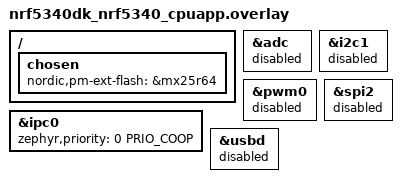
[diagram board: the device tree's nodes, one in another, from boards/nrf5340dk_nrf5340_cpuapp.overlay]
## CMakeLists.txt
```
#
# Copyright (c) 2023 Nordic Semiconductor ASA
#
# SPDX-License-Identifier: LicenseRef-Nordic-5-Clause
#

cmake_minimum_required(VERSION 3.20.0)

find_package(Zephyr HINTS $ENV{ZEPHYR_BASE})

project(matter-bridge)

# Enable GNU STD support.
include(${ZEPHYR_CONNECTEDHOMEIP_MODULE_DIR}/config/nrfconnect/app/enable-gnu-std.cmake)

# NORDIC SDK APP START

# Include all source files that are located in the Matter common directory.
include(${ZEPHYR_NRF_MODULE_DIR}/samples/matter/common/cmake/source_common.cmake)

# Include Data Model utils
include(${ZEPHYR_NRF_MODULE_DIR}/samples/matter/common/cmake/data_model.cmake)

include(${ZEPHYR_NRF_MODULE_DIR}/samples/matter/common/cmake/zap_helpers.cmake)
ncs_get_zap_parent_dir(ZAP_PARENT_DIR)

target_include_directories(app PRIVATE
  src
  src/bridged_device_types
  ${ZAP_PARENT_DIR}
  src/core/util
  src/core
)

target_sources(app PRIVATE
  src/app_task.cpp
  src/main.cpp
  src/bridge_shell.cpp
  src/zcl_callbacks.cpp
  src/core/bridge_manager.cpp
  src/core/matter_bridged_device.cpp
  src/core/bridge_storage_manager.cpp
  src/core/bridged_device_data_provider.cpp
  ${ZEPHYR_NRF_MODULE_DIR}/samples/matter/common/src/binding/binding_handler.cpp
)

if(CONFIG_BRIDGED_DEVICE_BT)
  target_sources(app PRIVATE
    src/ble/ble_connectivity_manager.cpp
    src/ble/ble_bridged_device_factory.cpp
  )
  target_include_directories(app PRIVATE
    src/ble
    src/ble/data_providers
  )

if(CONFIG_BRIDGE_ONOFF_LIGHT_BRIDGED_DEVICE AND (CONFIG_BRIDGE_GENERIC_SWITCH_BRIDGED_DEVICE OR CONFIG_BRIDGE_ONOFF_LIGHT_SWITCH_BRIDGED_DEVICE))
  target_sources(app PRIVATE
    src/bridged_device_types/onoff_light.cpp
    src/ble/data_providers/ble_lbs_data_provider.cpp
  )

if(CONFIG_BRIDGE_GENERIC_SWITCH_BRIDGED_DEVICE)
  target_sources(app PRIVATE src/bridged_device_types/generic_switch.cpp)
endif()

if(CONFIG_BRIDGE_ONOFF_LIGHT_SWITCH_BRIDGED_DEVICE)
  target_sources(app PRIVATE
    src/bridged_device_types/onoff_light_switch.cpp
  )
endif()

endif() # CONFIG_BRIDGE_ONOFF_LIGHT_BRIDGED_DEVICE AND (CONFIG_BRIDGE_GENERIC_SWITCH_BRIDGED_DEVICE OR CONFIG_BRIDGE_ONOFF_LIGHT_SWITCH_BRIDGED_DEVICE)

if(CONFIG_BRIDGE_HUMIDITY_SENSOR_BRIDGED_DEVICE)
  target_sources(app PRIVATE
    src/bridged_device_types/humidity_sensor.cpp
  )
endif() # CONFIG_BRIDGE_HUMIDITY_SENSOR_BRIDGED_DEVICE

if(CONFIG_BRIDGE_TEMPERATURE_SENSOR_BRIDGED_DEVICE)
  target_sources(app PRIVATE
    src/bridged_device_types/temperature_sensor.cpp
  )
endif() # CONFIG_BRIDGE_TEMPERATURE_SENSOR_BRIDGED_DEVICE

# Assume it makes no sense to support BLE environmental sensor without all Matter counterparts
if(CONFIG_BRIDGE_TEMPERATURE_SENSOR_BRIDGED_DEVICE AND CONFIG_BRIDGE_HUMIDITY_SENSOR_BRIDGED_DEVICE)
  target_sources(app PRIVATE
    src/ble/data_providers/ble_environmental_data_provider.cpp
)
endif() # CONFIG_BRIDGE_TEMPERATURE_SENSOR_BRIDGED_DEVICE AND CONFIG_BRIDGE_HUMIDITY_SENSOR_BRIDGED_DEVICE

else()
  target_sources(app PRIVATE
    src/simulated_providers/simulated_bridged_device_factory.cpp
  )
  target_include_directories(app PRIVATE src/simulated_providers)

if(CONFIG_BRIDGE_ONOFF_LIGHT_BRIDGED_DEVICE AND (CONFIG_BRIDGE_GENERIC_SWITCH_BRIDGED_DEVICE OR CONFIG_BRIDGE_ONOFF_LIGHT_SWITCH_BRIDGED_DEVICE))
  target_sources(app PRIVATE
    src/bridged_device_types/onoff_light.cpp
    src/simulated_providers/simulated_onoff_light_data_provider.cpp
  )

if(CONFIG_BRIDGE_GENERIC_SWITCH_BRIDGED_DEVICE)
  target_sources(app PRIVATE
    src/bridged_device_types/generic_switch.cpp
    src/simulated_providers/simulated_generic_switch_data_provider.cpp
  )
endif()

if(CONFIG_BRIDGE_ONOFF_LIGHT_SWITCH_BRIDGED_DEVICE)
  target_sources(app PRIVATE
    src/bridged_device_types/onoff_light_switch.cpp
    src/simulated_providers/simulated_onoff_light_switch_data_provider.cpp
  )
endif()

endif() # CONFIG_BRIDGE_ONOFF_LIGHT_BRIDGED_DEVICE AND (CONFIG_BRIDGE_GENERIC_SWITCH_BRIDGED_DEVICE OR CONFIG_BRIDGE_ONOFF_LIGHT_SWITCH_BRIDGED_DEVICE))

if(CONFIG_BRIDGE_TEMPERATURE_SENSOR_BRIDGED_DEVICE)
  target_sources(app PRIVATE
    src/bridged_device_types/temperature_sensor.cpp
    src/simulated_providers/simulated_temperature_sensor_data_provider.cpp
  )
endif() # CONFIG_BRIDGE_TEMPERATURE_SENSOR_BRIDGED_DEVICE

if(CONFIG_BRIDGE_HUMIDITY_SENSOR_BRIDGED_DEVICE)
  target_sources(app PRIVATE
    src/bridged_device_types/humidity_sensor.cpp
    src/simulated_providers/simulated_humidity_sensor_data_provider.cpp
  )
endif() # CONFIG_BRIDGE_HUMIDITY_SENSOR_BRIDGED_DEVICE

endif() # CONFIG_BRIDGED_DEVICE_BT

ncs_configure_data_model()
# NORDIC SDK APP END
```

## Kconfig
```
#
# Copyright (c) 2023 Nordic Semiconductor
#
# SPDX-License-Identifier: LicenseRef-Nordic-5-Clause
#
mainmenu "Matter nRF Connect Bridge Example Application"

config BRIDGE_ONOFF_LIGHT_BRIDGED_DEVICE
	bool "Support for OnOff Light bridged device"
	default y

config BRIDGE_TEMPERATURE_SENSOR_BRIDGED_DEVICE
	bool "Support for Temperature Sensor bridged device"
	default y

config BRIDGE_HUMIDITY_SENSOR_BRIDGED_DEVICE
	bool "Support for Humidity Sensor bridged device"
	default y

choice BRIDGE_SWITCH_BRIDGED_DEVICE
	prompt "Bridged device switch implementation"
	default BRIDGE_GENERIC_SWITCH_BRIDGED_DEVICE

config BRIDGE_GENERIC_SWITCH_BRIDGED_DEVICE
	bool "Support for Generic Switch bridged device"

config BRIDGE_ONOFF_LIGHT_SWITCH_BRIDGED_DEVICE
	bool "Support for OnOff Light Switch bridged device"

endchoice

choice BRIDGED_DEVICE_IMPLEMENTATION
	prompt "Bridged Device implementation"
	default BRIDGED_DEVICE_SIMULATED

config BRIDGED_DEVICE_SIMULATED
	bool "Simulated Bridged Device"
	help
	  Enables using simulated bridged devices that do not perform
	  real operations, but emulate exemplary data to imitate the real
	  device behavior.

config BRIDGED_DEVICE_BT
	bool "Bluetooth LE Bridged Device"
	help
	  Enables using real bridged devices that communicate with the Matter bridge device
	  over Bluetooth LE.

endchoice

if BRIDGED_DEVICE_SIMULATED

choice BRIDGED_DEVICE_SIMULATED_ONOFF_IMPLEMENTATION
	prompt "Simulated bridged onoff device implementation"
	default BRIDGED_DEVICE_SIMULATED_ONOFF_SHELL

config BRIDGED_DEVICE_SIMULATED_ONOFF_AUTOMATIC
	bool "Automatically simulated bridged onoff device"
	help
	  Enables using simulated bridged onoff device that
	  automatically changes its state periodically.

config BRIDGED_DEVICE_SIMULATED_ONOFF_SHELL
	bool "Shell controlled simulated bridged onoff device"
	help
	  Enables using simulated bridged onoff device that is
	  controlled by shell commands.

endchoice

endif

if BRIDGED_DEVICE_BT

config BT_CENTRAL
	default y

config BT_SCAN
	default y

# Configure how many Bluetooth LE devices the Matter bridge can support (the final number is given value - 1, as 1 connection is used for the Matter Bluetooth LE service).
config BT_MAX_CONN
	default 10

config BT_SCAN_FILTER_ENABLE
	default y

# Configure how many Bluetooth LE service UUIDs the Matter bridge can scan.
config BT_SCAN_UUID_CNT
	default 2

config BT_SCAN_ADDRESS_CNT
	default 1

config BT_GATT_CLIENT
	default y

config BT_GATT_DM
	default y

config BT_EXT_ADV
	default y

config BT_SMP
	default y

if BT_SMP

config BT_SETTINGS
	default y

# Configure how many Bluetooth LE devices will be paired with Matter bridge. Assuming it will be only bridged devices, it should be set to BT_MAX_CONN - 1.
config BT_MAX_PAIRED
	default 9

# Use two Bluetooth LE identities. The first one is used by the peripheral for Matter service advertising purposes, and the other is used by the Matter bridge central.
config BT_ID_MAX
	default 2

config BT_EXT_ADV_LEGACY_SUPPORT
	default y

endif

config BRIDGE_BLE_DEVICE_POLLING_INTERVAL
	int "BLE humidity measurement readout polling interval in ms"
	default 3000

endif

if BRIDGE_TEMPERATURE_SENSOR_BRIDGED_DEVICE

config BRIDGE_TEMPERATURE_SENSOR_MIN_MEASURED_VALUE
	int "Default minimum measured value allowed by the bridged temperature sensor device"
	default -20

config BRIDGE_TEMPERATURE_SENSOR_MAX_MEASURED_VALUE
	int "Default maximum measured value allowed by the bridged temperature sensor device"
	default 60

endif

if BRIDGE_HUMIDITY_SENSOR_BRIDGED_DEVICE

config BRIDGE_HUMIDITY_SENSOR_MIN_MEASURED_VALUE
	int "Default minimum measured value allowed by the bridged humidity sensor device"
	default 0

config BRIDGE_HUMIDITY_SENSOR_MAX_MEASURED_VALUE
	int "Default maximum measured value allowed by the bridged humidity sensor device"
	default 100

endif

# Enable Read Client functionality for all build configurations.
config CHIP_ENABLE_READ_CLIENT
	default y

config NCS_SAMPLE_MATTER_PERSISTENT_STORAGE
	default y

config BRIDGE_SMART_PLUG_SUPPORT
	bool "Additional endpoint implementing Matter smart plug functionality"

# Sample configuration used for Thread networking
if OPENTHREAD

choice OPENTHREAD_NORDIC_LIBRARY_CONFIGURATION
	default OPENTHREAD_NORDIC_LIBRARY_FTD
endchoice

choice OPENTHREAD_DEVICE_TYPE
	default OPENTHREAD_FTD
endchoice

endif # OPENTHREAD

config CHIP_WIFI
	default y if SHIELD_NRF7002EB2

# Dummy Kconfig just to select experimental for some of the configurations.
config BRIDGE_EXPERIMENTAL
	bool
	default y if OPENTHREAD || BRIDGE_SMART_PLUG_SUPPORT
	select EXPERIMENTAL

source "$(ZEPHYR_CONNECTEDHOMEIP_MODULE_DIR)/config/nrfconnect/chip-module/Kconfig.features"
source "$(ZEPHYR_CONNECTEDHOMEIP_MODULE_DIR)/config/nrfconnect/chip-module/Kconfig.defaults"
source "$(ZEPHYR_NRF_MODULE_DIR)/applications/matter_bridge/src/core/Kconfig"
source "$(ZEPHYR_NRF_MODULE_DIR)/samples/matter/common/src/Kconfig"
source "Kconfig.zephyr"
```

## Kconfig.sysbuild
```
#
# Copyright (c) 2023 Nordic Semiconductor ASA
#
# SPDX-License-Identifier: LicenseRef-Nordic-5-Clause
#

#### Radio core
config NRF_DEFAULT_IPC_RADIO
	default y

# Enable Bluetooth serialization to network core
config NETCORE_IPC_RADIO_BT_HCI_IPC
	default y

#### Bootloader
choice BOOTLOADER
	default BOOTLOADER_MCUBOOT
endchoice

# Enable IEEE802.15.4 serialization to network core
# This config automatically pulls in the `overlay-802154.conf` in the ipc_radio image
config NETCORE_IPC_RADIO_IEEE802154
	default y if SOC_SERIES_NRF53 && !WIFI_NRF70

if BOOTLOADER_MCUBOOT

#### DFU multi-image support
config DFU_MULTI_IMAGE_PACKAGE_BUILD
	default y

config DFU_MULTI_IMAGE_PACKAGE_APP
	default y

#### DFU network core configuration
if SOC_SERIES_NRF53

choice MCUBOOT_MODE
	default MCUBOOT_MODE_OVERWRITE_ONLY
endchoice

choice BOOT_SIGNATURE_TYPE
	default BOOT_SIGNATURE_TYPE_RSA
endchoice

config SECURE_BOOT_NETCORE
	default y

config NETCORE_APP_UPDATE
	default y

config MCUBOOT_NRF53_MULTI_IMAGE_UPDATE
	default y if NETCORE_APP_UPDATE

config DFU_MULTI_IMAGE_PACKAGE_NET
	default y

endif # SOC_SERIES_NRF53

endif # BOOTLOADER_MCUBOOT

#### Enable generating factory data
config MATTER_FACTORY_DATA_GENERATE
	default y

source "share/sysbuild/Kconfig"
```

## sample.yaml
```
sample:
  description: Matter Bridge
  name: Matter Bridge application
common:
  tags:
    - sysbuild
    - ci_applications_matter
tests:
  applications.matter_bridge.release:
    sysbuild: true
    build_only: true
    extra_args:
      - FILE_SUFFIX=release
      - CONFIG_BRIDGE_GENERIC_SWITCH_BRIDGED_DEVICE=n
      - CONFIG_BRIDGE_ONOFF_LIGHT_SWITCH_BRIDGED_DEVICE=y
    integration_platforms:
      - nrf5340dk/nrf5340/cpuapp
      - nrf54lm20dk/nrf54lm20b/cpuapp
      - nrf54lm20dk/nrf54lm20a/cpuapp
    platform_allow:
      - nrf5340dk/nrf5340/cpuapp
      - nrf54lm20dk/nrf54lm20b/cpuapp
      - nrf54lm20dk/nrf54lm20a/cpuapp
  applications.matter_bridge.nrf7002eb2.release:
    sysbuild: true
    build_only: true
    extra_args:
      - FILE_SUFFIX=release
      - CONFIG_BRIDGE_GENERIC_SWITCH_BRIDGED_DEVICE=n
      - CONFIG_BRIDGE_ONOFF_LIGHT_SWITCH_BRIDGED_DEVICE=y
      - matter_bridge_SHIELD=nrf7002eb2
      - SB_CONFIG_WIFI_NRF70=y
    integration_platforms:
      - nrf54lm20dk/nrf54lm20b/cpuapp
      - nrf54lm20dk/nrf54lm20a/cpuapp
    platform_allow:
      - nrf54lm20dk/nrf54lm20b/cpuapp
      - nrf54lm20dk/nrf54lm20a/cpuapp
  applications.matter_bridge.debug:
    sysbuild: true
    build_only: true
    extra_args:
      - CONFIG_BRIDGE_GENERIC_SWITCH_BRIDGED_DEVICE=n
      - CONFIG_BRIDGE_ONOFF_LIGHT_SWITCH_BRIDGED_DEVICE=y
    integration_platforms:
      - nrf5340dk/nrf5340/cpuapp
      - nrf54lm20dk/nrf54lm20b/cpuapp
      - nrf54lm20dk/nrf54lm20a/cpuapp
    platform_allow:
      - nrf5340dk/nrf5340/cpuapp
      - nrf54lm20dk/nrf54lm20b/cpuapp
      - nrf54lm20dk/nrf54lm20a/cpuapp
  applications.matter_bridge.nrf7002eb2.debug:
    sysbuild: true
    build_only: true
    extra_args:
      - CONFIG_BRIDGE_GENERIC_SWITCH_BRIDGED_DEVICE=n
      - CONFIG_BRIDGE_ONOFF_LIGHT_SWITCH_BRIDGED_DEVICE=y
      - matter_bridge_SHIELD=nrf7002eb2
      - SB_CONFIG_WIFI_NRF70=y
    integration_platforms:
      - nrf54lm20dk/nrf54lm20b/cpuapp
      - nrf54lm20dk/nrf54lm20a/cpuapp
    platform_allow:
      - nrf54lm20dk/nrf54lm20b/cpuapp
      - nrf54lm20dk/nrf54lm20a/cpuapp
  applications.matter_bridge.br_ble:
    sysbuild: true
    build_only: true
    extra_args:
      - CONFIG_BRIDGED_DEVICE_BT=y
      - CONFIG_BRIDGE_GENERIC_SWITCH_BRIDGED_DEVICE=n
      - CONFIG_BRIDGE_ONOFF_LIGHT_SWITCH_BRIDGED_DEVICE=y
    integration_platforms:
      - nrf5340dk/nrf5340/cpuapp
      - nrf54lm20dk/nrf54lm20b/cpuapp
      - nrf54lm20dk/nrf54lm20a/cpuapp
    platform_allow:
      - nrf5340dk/nrf5340/cpuapp
      - nrf54lm20dk/nrf54lm20b/cpuapp
      - nrf54lm20dk/nrf54lm20a/cpuapp
  applications.matter_bridge.nrf7002eb2.br_ble:
    sysbuild: true
    build_only: true
    extra_args:
      - CONFIG_BRIDGED_DEVICE_BT=y
      - CONFIG_BRIDGE_GENERIC_SWITCH_BRIDGED_DEVICE=n
      - CONFIG_BRIDGE_ONOFF_LIGHT_SWITCH_BRIDGED_DEVICE=y
      - matter_bridge_SHIELD=nrf7002eb2
      - SB_CONFIG_WIFI_NRF70=y
    integration_platforms:
      - nrf54lm20dk/nrf54lm20b/cpuapp
      - nrf54lm20dk/nrf54lm20a/cpuapp
    platform_allow:
      - nrf54lm20dk/nrf54lm20b/cpuapp
      - nrf54lm20dk/nrf54lm20a/cpuapp
  applications.matter_bridge.release.br_ble:
    sysbuild: true
    build_only: true
    extra_args:
      - FILE_SUFFIX=release
      - CONFIG_BRIDGED_DEVICE_BT=y
      - CONFIG_BRIDGE_GENERIC_SWITCH_BRIDGED_DEVICE=n
      - CONFIG_BRIDGE_ONOFF_LIGHT_SWITCH_BRIDGED_DEVICE=y
    integration_platforms:
      - nrf5340dk/nrf5340/cpuapp
      - nrf54lm20dk/nrf54lm20b/cpuapp
      - nrf54lm20dk/nrf54lm20a/cpuapp
    platform_allow:
      - nrf5340dk/nrf5340/cpuapp
      - nrf54lm20dk/nrf54lm20b/cpuapp
      - nrf54lm20dk/nrf54lm20a/cpuapp
  applications.matter_bridge.nrf7002eb2.release.br_ble:
    sysbuild: true
    build_only: true
    extra_args:
      - FILE_SUFFIX=release
      - CONFIG_BRIDGED_DEVICE_BT=y
      - CONFIG_BRIDGE_GENERIC_SWITCH_BRIDGED_DEVICE=n
      - CONFIG_BRIDGE_ONOFF_LIGHT_SWITCH_BRIDGED_DEVICE=y
      - matter_bridge_SHIELD=nrf7002eb2
      - SB_CONFIG_WIFI_NRF70=y
    integration_platforms:
      - nrf54lm20dk/nrf54lm20b/cpuapp
      - nrf54lm20dk/nrf54lm20a/cpuapp
    platform_allow:
      - nrf54lm20dk/nrf54lm20b/cpuapp
      - nrf54lm20dk/nrf54lm20a/cpuapp
  applications.matter_bridge.br_ble.smp_dfu:
    sysbuild: true
    build_only: true
    extra_args:
      - CONFIG_CHIP_DFU_OVER_BT_SMP=y
      - CONFIG_BRIDGED_DEVICE_BT=y
      - CONFIG_BRIDGE_GENERIC_SWITCH_BRIDGED_DEVICE=n
      - CONFIG_BRIDGE_ONOFF_LIGHT_SWITCH_BRIDGED_DEVICE=y
    integration_platforms:
      - nrf54lm20dk/nrf54lm20b/cpuapp
      - nrf54lm20dk/nrf54lm20a/cpuapp
    platform_allow:
      - nrf54lm20dk/nrf54lm20b/cpuapp
      - nrf54lm20dk/nrf54lm20a/cpuapp
  applications.matter_bridge.nrf7002eb2.br_ble.smp_dfu:
    sysbuild: true
    build_only: true
    extra_args:
      - CONFIG_CHIP_DFU_OVER_BT_SMP=y
      - CONFIG_BRIDGED_DEVICE_BT=y
      - CONFIG_BRIDGE_GENERIC_SWITCH_BRIDGED_DEVICE=n
      - CONFIG_BRIDGE_ONOFF_LIGHT_SWITCH_BRIDGED_DEVICE=y
      - matter_bridge_SHIELD=nrf7002eb2
      - SB_CONFIG_WIFI_NRF70=y
    integration_platforms:
      - nrf54lm20dk/nrf54lm20b/cpuapp
      - nrf54lm20dk/nrf54lm20a/cpuapp
    platform_allow:
      - nrf54lm20dk/nrf54lm20b/cpuapp
      - nrf54lm20dk/nrf54lm20a/cpuapp
  applications.matter_bridge.br_ble.memory_profiling:
    sysbuild: true
    build_only: true
    extra_args:
      - CONFIG_BRIDGE_GENERIC_SWITCH_BRIDGED_DEVICE=n
      - CONFIG_BRIDGE_ONOFF_LIGHT_SWITCH_BRIDGED_DEVICE=y
      - CONFIG_CHIP_MEMORY_PROFILING=y
      - CONFIG_BRIDGED_DEVICE_BT=y
      - CONFIG_BRIDGE_MIGRATE_VERSION_1=n
    integration_platforms:
      - nrf5340dk/nrf5340/cpuapp
      - nrf54lm20dk/nrf54lm20b/cpuapp
      - nrf54lm20dk/nrf54lm20a/cpuapp
    platform_allow:
      - nrf5340dk/nrf5340/cpuapp
      - nrf54lm20dk/nrf54lm20b/cpuapp
      - nrf54lm20dk/nrf54lm20a/cpuapp
  applications.matter_bridge.memory_profiling:
    sysbuild: true
    build_only: true
    extra_args:
      - CONFIG_BRIDGE_GENERIC_SWITCH_BRIDGED_DEVICE=n
      - CONFIG_BRIDGE_ONOFF_LIGHT_SWITCH_BRIDGED_DEVICE=y
      - CONFIG_CHIP_MEMORY_PROFILING=y
    integration_platforms:
      - nrf54lm20dk/nrf54lm20b/cpuapp
      - nrf54lm20dk/nrf54lm20a/cpuapp
    platform_allow:
      - nrf54lm20dk/nrf54lm20b/cpuapp
      - nrf54lm20dk/nrf54lm20a/cpuapp
  applications.matter_bridge.smart_plug:
    sysbuild: true
    build_only: true
    extra_args:
      - EXTRA_CONF_FILE=onoff_plug.conf
    integration_platforms:
      - nrf5340dk/nrf5340/cpuapp
    platform_allow: nrf5340dk/nrf5340/cpuapp
```

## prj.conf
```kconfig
#
# Copyright (c) 2023 Nordic Semiconductor ASA
#
# SPDX-License-Identifier: LicenseRef-Nordic-5-Clause
#

# This sample uses Kconfig.defaults to set options common for all
# samples. This file should contain only options specific for this sample
# or overrides of default values.

# Enable CHIP
CONFIG_CHIP=y
CONFIG_CHIP_PROJECT_CONFIG="src/chip_project_config.h"
CONFIG_CHIP_DEVICE_PRODUCT_NAME="Matter Bridge"

# Configure ZAP file name
CONFIG_NCS_SAMPLE_MATTER_ZAP_FILE_PATH="${APPLICATION_CONFIG_DIR}/src/default_zap/bridge.zap"

# 32770 == 0x8002 (example bridge)
CONFIG_CHIP_DEVICE_PRODUCT_ID=32770
CONFIG_STD_CPP17=y

# Enable Matter pairing automatically on application start.
CONFIG_CHIP_ENABLE_PAIRING_AUTOSTART=y

# Enable Matter extended announcement and increase duration to 1 hour.
CONFIG_CHIP_BLE_EXT_ADVERTISING=y
CONFIG_CHIP_BLE_ADVERTISING_DURATION=60

# Add support for LEDs and buttons on Nordic development kits
CONFIG_DK_LIBRARY=y

# Bluetooth Low Energy configuration
CONFIG_BT_DEVICE_NAME="MatterBridge"

# Other settings
CONFIG_THREAD_NAME=y
CONFIG_MPU_STACK_GUARD=y
CONFIG_RESET_ON_FATAL_ERROR=n
CONFIG_CHIP_LIB_SHELL=y
CONFIG_NCS_SAMPLE_MATTER_TEST_SHELL=y

# Reduce assert verbosity to save flash space.
CONFIG_ASSERT_NO_FILE_INFO=y

# Disable NFC onboarding
CONFIG_CHIP_NFC_ONBOARDING_PAYLOAD=n

# Reduce application size
CONFIG_USE_SEGGER_RTT=n

# Enable Factory Data feature
CONFIG_CHIP_FACTORY_DATA=y
CONFIG_CHIP_FACTORY_DATA_BUILD=y

# Increase heap size to accommodate the memory required for additional bridged devices.
CONFIG_CHIP_MALLOC_SYS_HEAP_SIZE=16384

# Enable Shell
CONFIG_SHELL=y
```

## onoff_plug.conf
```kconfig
#
# Copyright (c) 2026 Nordic Semiconductor ASA
#
# SPDX-License-Identifier: LicenseRef-Nordic-5-Clause
#

CONFIG_BRIDGE_SMART_PLUG_SUPPORT=y

CONFIG_NCS_SAMPLE_MATTER_ZAP_FILE_PATH="${APPLICATION_CONFIG_DIR}/src/onoff_plug_zap/bridge.zap"
```

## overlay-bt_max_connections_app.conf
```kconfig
#
# Copyright (c) 2023 Nordic Semiconductor ASA
#
# SPDX-License-Identifier: LicenseRef-Nordic-5-Clause
#

# Set 20 BLE connections, as it is an upper limit supported by the Soft Device Controller.
CONFIG_BT_MAX_CONN=20

# Set ACL RX count to CONFIG_BT_MAX_CONN + 1, as it is expected that CONFIG_BT_BUF_ACL_RX_COUNT > CONFIG_BT_MAX_CONN.
CONFIG_BT_BUF_ACL_RX_COUNT=21

# Set buffer sizes in a consistent way with the ones used by the network core.
CONFIG_BT_BUF_ACL_RX_SIZE=84
CONFIG_BT_BUF_ACL_TX_SIZE=84

# Set MTU size to fit in the single buffer and avoid fragmentation (BUF_SIZE = MTU_SIZE + 4 B of L2CAP header).
CONFIG_BT_L2CAP_TX_MTU=80

# Set max number of bridged BLE devices, which is CONFIG_BT_MAX_CONN-1, as 1 connection is reserved for Matter.
CONFIG_BRIDGE_MAX_BRIDGED_DEVICES_NUMBER=19
CONFIG_BT_MAX_PAIRED=19

# Assume that every bridged device uses only 1 endpoint, however it can be increased if specific use case requires it.
CONFIG_BRIDGE_MAX_DYNAMIC_ENDPOINTS_NUMBER=19
```

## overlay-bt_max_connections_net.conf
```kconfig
#
# Copyright (c) 2023 Nordic Semiconductor ASA
#
# SPDX-License-Identifier: LicenseRef-Nordic-5-Clause
#

# Set 20 BLE connections, as it is an upper limit supported by the Soft Device Controller
CONFIG_BT_MAX_CONN=20

# Decrease stack and buffer sizes to free some RAM and support 20 BLE connections
CONFIG_MAIN_STACK_SIZE=512
CONFIG_SYSTEM_WORKQUEUE_STACK_SIZE=512
CONFIG_BT_BUF_ACL_RX_SIZE=84
CONFIG_BT_BUF_ACL_TX_SIZE=84
CONFIG_BT_CTLR_DATA_LENGTH_MAX=84
```

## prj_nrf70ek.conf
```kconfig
#
# Copyright (c) 2023 Nordic Semiconductor ASA
#
# SPDX-License-Identifier: LicenseRef-Nordic-5-Clause
#

# This sample uses Kconfig.defaults to set options common for all
# samples. This file should contain only options specific for this sample
# or overrides of default values.

# Enable CHIP
CONFIG_CHIP=y
CONFIG_CHIP_PROJECT_CONFIG="src/chip_project_config.h"
# 32770 == 0x8002 (example bridge)
CONFIG_CHIP_DEVICE_PRODUCT_ID=32770
CONFIG_STD_CPP17=y

# Enable Matter pairing automatically on application start.
CONFIG_CHIP_ENABLE_PAIRING_AUTOSTART=y

# Enable Matter extended announcement and increase duration to 1 hour.
CONFIG_CHIP_BLE_EXT_ADVERTISING=y
CONFIG_CHIP_BLE_ADVERTISING_DURATION=60

# Add support for LEDs and buttons on Nordic development kits
CONFIG_DK_LIBRARY=y

# Bluetooth Low Energy configuration
CONFIG_BT_DEVICE_NAME="MatterBridge"

# Other settings
CONFIG_THREAD_NAME=y
CONFIG_MPU_STACK_GUARD=y
CONFIG_RESET_ON_FATAL_ERROR=n
CONFIG_CHIP_LIB_SHELL=y

# Reduce assert verbosity to save flash space.
CONFIG_ASSERT_NO_FILE_INFO=y

# Disable NFC commissioning
CONFIG_CHIP_NFC_COMMISSIONING=n

# Reduce application size
CONFIG_USE_SEGGER_RTT=n

# Enable Factory Data feature
CONFIG_CHIP_FACTORY_DATA=y
CONFIG_CHIP_FACTORY_DATA_BUILD=y

# Enable LTO to decrease the flash usage.
CONFIG_LTO=y
CONFIG_ISR_TABLES_LOCAL_DECLARATION=y
```

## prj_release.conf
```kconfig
#
# Copyright (c) 2023 Nordic Semiconductor ASA
#
# SPDX-License-Identifier: LicenseRef-Nordic-5-Clause
#

# This sample uses Kconfig.defaults to set options common for all
# samples. This file should contain only options specific for this sample
# or overrides of default values.

# Enable CHIP
CONFIG_CHIP=y
CONFIG_CHIP_PROJECT_CONFIG="src/chip_project_config.h"
CONFIG_CHIP_DEVICE_PRODUCT_NAME="Matter Bridge"

# Configure ZAP file name
CONFIG_NCS_SAMPLE_MATTER_ZAP_FILE_PATH="${APPLICATION_CONFIG_DIR}/src/default_zap/bridge.zap"

# 32770 == 0x8002 (example bridge)
CONFIG_CHIP_DEVICE_PRODUCT_ID=32770
CONFIG_STD_CPP17=y

# Enable Matter pairing automatically on application start.
CONFIG_CHIP_ENABLE_PAIRING_AUTOSTART=y

# Enable Matter extended announcement and increase duration to 1 hour.
CONFIG_CHIP_BLE_EXT_ADVERTISING=y
CONFIG_CHIP_BLE_ADVERTISING_DURATION=60

# Add support for LEDs and buttons on Nordic development kits
CONFIG_DK_LIBRARY=y

# Bluetooth Low Energy configuration
CONFIG_BT_DEVICE_NAME="MatterBridge"

# Enable system reset on fatal error
CONFIG_RESET_ON_FATAL_ERROR=y

# Disable all debug features
CONFIG_USE_SEGGER_RTT=n
CONFIG_OPENTHREAD_SHELL=n
CONFIG_LOG=n
CONFIG_LOG_MODE_MINIMAL=n
CONFIG_ASSERT_VERBOSE=n
CONFIG_ASSERT_NO_FILE_INFO=y
CONFIG_PRINTK=n
CONFIG_PRINTK_SYNC=n
CONFIG_THREAD_NAME=n
CONFIG_BOOT_BANNER=n

# Disable NFC onboarding
CONFIG_CHIP_NFC_ONBOARDING_PAYLOAD=n

# Enable Factory Data feature
CONFIG_CHIP_FACTORY_DATA=y
CONFIG_CHIP_FACTORY_DATA_BUILD=y

# Enable the Read Client for binding purposes
CONFIG_CHIP_ENABLE_READ_CLIENT=y

# Enable Watchdog
CONFIG_NCS_SAMPLE_MATTER_WATCHDOG=y

# Enable LTO to decrease the flash usage.
CONFIG_LTO=y
CONFIG_ISR_TABLES_LOCAL_DECLARATION=y

# Increase heap size to accommodate the memory required for additional bridged devices.
CONFIG_CHIP_MALLOC_SYS_HEAP_SIZE=16384

# Enable Shell
CONFIG_SHELL=y
```

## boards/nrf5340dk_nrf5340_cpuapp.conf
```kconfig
#
# Copyright (c) 2023 Nordic Semiconductor ASA
#
# SPDX-License-Identifier: LicenseRef-Nordic-5-Clause
#

# Set 8 BLE connections, as it is an upper limit supported caused by RAM usage due to using Thread and BLE at same time.
CONFIG_BT_MAX_CONN=8

# Set buffer sizes in a consistent way with the ones used by the network core.
CONFIG_BT_BUF_ACL_RX_SIZE=69
CONFIG_BT_BUF_ACL_TX_SIZE=69

# Set MTU size to fit in the single buffer and avoid fragmentation (BUF_SIZE = MTU_SIZE + 4 B of L2CAP header).
CONFIG_BT_L2CAP_TX_MTU=65

# Set max number of bridged BLE devices, which is CONFIG_BT_MAX_CONN-1, as 1 connection is reserved for Matter.
CONFIG_BRIDGE_MAX_BRIDGED_DEVICES_NUMBER=9
CONFIG_BT_MAX_PAIRED=9

# Assume that every bridged device uses 2 endpoints, however it can be increased if specific use case requires it.
CONFIG_BRIDGE_MAX_DYNAMIC_ENDPOINTS_NUMBER=18
# 15.4 RX buffers were decreased to save RAM
CONFIG_NRF_802154_RX_BUFFERS=14

# Enable LTO to decrease the flash usage.
CONFIG_LTO=y
CONFIG_ISR_TABLES_LOCAL_DECLARATION=y
```

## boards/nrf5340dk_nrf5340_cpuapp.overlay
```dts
/*
 * Copyright (c) 2024 Nordic Semiconductor ASA
 *
 * SPDX-License-Identifier: LicenseRef-Nordic-5-Clause
 */

#include <zephyr/dt-bindings/ipc_service/static_vrings.h>

/ {
	chosen {
		nordic,pm-ext-flash = &mx25r64;
	};
};

/* Set IPC thread priority to the highest value to not collide with other threads. */
&ipc0 {
	zephyr,priority = <0 PRIO_COOP>;
};

/* Disable unused peripherals to reduce power consumption */
&adc {
	status = "disabled";
};

&i2c1 {
	status = "disabled";
};

&pwm0 {
	status = "disabled";
};

&spi2 {
	status = "disabled";
};

&usbd {
	status = "disabled";
};
```

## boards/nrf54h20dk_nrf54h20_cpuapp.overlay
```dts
/*
 * Copyright (c) 2024 Nordic Semiconductor ASA
 *
 * SPDX-License-Identifier: LicenseRef-Nordic-5-Clause
 */

// Base path of the following includes points to the nrf/include directory.
#include <../samples/matter/common/dts/nrf54h20/nrf54h20_cpuapp_peripherals.dtsi>
#include <../samples/matter/common/dts/nrf54h20/nrf54h20_cpuapp_memory_map.dtsi>
#include <../samples/matter/common/dts/nrf54h20/nrf54h20_ram_allocation.dtsi>

/delete-node/ &cpuapp_rx_partitions;
/delete-node/ &cpuapp_rw_partitions;

&mram1x {
	erase-block-size = <0x1000>;
	write-block-size = <0x10>;

	cpuapp_rx_partitions: cpuapp-rx-partitions {
		compatible = "nordic,owned-partitions", "fixed-partitions";
		status = "okay";
		nordic,access = <NRF_OWNER_ID_APPLICATION NRF_PERM_RXS>;
		#address-cells = <1>;
		#size-cells = <1>;

		companion_partition: partition@98000 {
			reg = <0x98000 DT_SIZE_K(64)>;
		};

		cpuapp_slot0_partition: partition@a8000 {
			reg = <0xa8000 DT_SIZE_K(948)>;
		};
	};

	cpuapp_rw_partitions: cpuapp-rw-partitions {
		compatible = "nordic,owned-partitions", "fixed-partitions";
		status = "okay";
		nordic,access = <NRF_OWNER_ID_APPLICATION NRF_PERM_RW>;
		#address-cells = <0x1>;
		#size-cells = <0x1>;

		storage_partition: partition@195000 {
			reg = <0x195000 DT_SIZE_K(32)>;
		};

		factory_data: partition@19D000 {
			reg = <0x19D000 DT_SIZE_K(4)>;
		};

		/* DFU partition to store SUIT manifests and Nordic Firmware update */
		dfu_partition: partition@19E000 {
			reg = <0x19E000 DT_SIZE_K(300)>;
		};
	};
};
```

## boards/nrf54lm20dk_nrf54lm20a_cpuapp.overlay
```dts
/*
 * Copyright (c) 2025 Nordic Semiconductor ASA
 *
 * SPDX-License-Identifier: LicenseRef-Nordic-5-Clause
 */

#include <samples/matter/nrf54lm20_cpuapp_partitions.dtsi>

/ {
	aliases {
		/* Use watchdog wdt31 as the application watchdog */
		watchdog0 = &wdt31;
	};

	chosen {
		nordic,pm-ext-flash = &mx25r64;
	};
};

&mx25r64 {
	status = "okay";
};

&wdt31 {
	status = "okay";
};
```

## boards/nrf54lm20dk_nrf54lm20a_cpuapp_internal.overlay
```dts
/*
 * Copyright (c) 2025 Nordic Semiconductor ASA
 *
 * SPDX-License-Identifier: LicenseRef-Nordic-5-Clause
 */

#include <samples/matter/nrf54lm20_cpuapp_internal_partitions.dtsi>

/ {
	aliases {
		/* Use watchdog wdt31 as the application watchdog */
		watchdog0 = &wdt31;
	};
};

&wdt31 {
	status = "okay";
};
```

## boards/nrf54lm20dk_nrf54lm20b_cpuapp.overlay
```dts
/*
 * Copyright (c) 2026 Nordic Semiconductor ASA
 *
 * SPDX-License-Identifier: LicenseRef-Nordic-5-Clause
 */

#include <samples/matter/nrf54lm20_cpuapp_partitions.dtsi>

/ {
	aliases {
		/* Use watchdog wdt31 as the application watchdog */
		watchdog0 = &wdt31;
	};

	chosen {
		nordic,pm-ext-flash = &mx25r64;
	};
};

&mx25r64 {
	status = "okay";
};

&wdt31 {
	status = "okay";
};
```

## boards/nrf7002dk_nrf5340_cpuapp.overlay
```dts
/*
 * Copyright (c) 2023 Nordic Semiconductor ASA
 *
 * SPDX-License-Identifier: LicenseRef-Nordic-5-Clause
 */

#include <zephyr/dt-bindings/ipc_service/static_vrings.h>

/ {
	chosen {
		nordic,pm-ext-flash = &mx25r64;
	};

	aliases {
		watchdog0 = &wdt0;
	};
};

/* Set IPC thread priority to the highest value to not collide with other threads. */
&ipc0 {
	zephyr,priority = <0 PRIO_COOP>;
};
```

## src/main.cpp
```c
/*
 * Copyright (c) 2023 Nordic Semiconductor ASA
 *
 * SPDX-License-Identifier: LicenseRef-Nordic-5-Clause
 */

#include "app_task.h"

#include <bridge/bridge_storage_manager.h>
#include <zephyr/logging/log.h>

LOG_MODULE_REGISTER(app, CONFIG_CHIP_APP_LOG_LEVEL);

int main()
{
	CHIP_ERROR err = AppTask::Instance().StartApp();

	LOG_ERR("Exited with code %" CHIP_ERROR_FORMAT, err.Format());
	return err == CHIP_NO_ERROR ? EXIT_SUCCESS : EXIT_FAILURE;
}

bool AppFactoryResetHandler()
{
	return Nrf::BridgeStorageManager::Instance().FactoryReset();
}
```

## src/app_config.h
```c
/*
 * Copyright (c) 2023 Nordic Semiconductor ASA
 *
 * SPDX-License-Identifier: LicenseRef-Nordic-5-Clause
 */

#pragma once

/* ---- Bridge App Config ---- */

#include "board_util.h"

#define FUNCTION_BUTTON DK_BTN1
#define FUNCTION_BUTTON_MASK DK_BTN1_MSK

#define BLE_ADVERTISEMENT_START_BUTTON DK_BTN2
#define BLE_ADVERTISEMENT_START_BUTTON_MASK DK_BTN2_MSK

#define SYSTEM_STATE_LED DK_LED1
#define FACTORY_RESET_SIGNAL_LED DK_LED2
```

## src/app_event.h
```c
/*
 * Copyright (c) 2023 Nordic Semiconductor ASA
 *
 * SPDX-License-Identifier: LicenseRef-Nordic-5-Clause
 */

#pragma once

#include <cstdint>

#include "event_types.h"

class LEDWidget;

enum class AppEventType : uint8_t { None = 0, Button, ButtonPushed, ButtonReleased, Timer, UpdateLedState };

enum class FunctionEvent : uint8_t { NoneSelected = 0, SoftwareUpdate = 0, FactoryReset };

struct AppEvent {
	union {
		struct {
			uint8_t PinNo;
			uint8_t Action;
		} ButtonEvent;
		struct {
			void *Context;
		} TimerEvent;
		struct {
			LEDWidget *LedWidget;
		} UpdateLedStateEvent;
	};

	AppEventType Type{ AppEventType::None };
	EventHandler Handler;
};
```

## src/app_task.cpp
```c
/*
 * Copyright (c) 2023 Nordic Semiconductor ASA
 *
 * SPDX-License-Identifier: LicenseRef-Nordic-5-Clause
 */

#include "app_task.h"

#ifdef CONFIG_BRIDGED_DEVICE_BT
#include "ble_bridged_device_factory.h"
#else
#include "simulated_bridged_device_factory.h"
#endif /* CONFIG_BRIDGED_DEVICE_BT */

#include "app/matter_init.h"
#include "app/task_executor.h"
#include "board/board.h"
#include "bridge_manager.h"
#include "bridge_storage_manager.h"
#include "clusters/identify.h"

#ifdef CONFIG_BRIDGED_DEVICE_BT
#include "ble_connectivity_manager.h"
#endif

#include <app-common/zap-generated/attributes/Accessors.h>
#include <app-common/zap-generated/ids/Attributes.h>
#include <app-common/zap-generated/ids/Clusters.h>
#include <setup_payload/OnboardingCodesUtil.h>

#ifdef CONFIG_BRIDGED_DEVICE_BT
#include <bluetooth/services/lbs.h>
#endif /* CONFIG_BRIDGED_DEVICE_BT */
#include <zephyr/logging/log.h>

#ifdef CONFIG_BRIDGE_SMART_PLUG_SUPPORT
#define APPLICATION_BUTTON_MASK DK_BTN2_MSK
#endif /* CONFIG_BRIDGE_SMART_PLUG_SUPPORT */

LOG_MODULE_DECLARE(app, CONFIG_CHIP_APP_LOG_LEVEL);

using namespace ::chip;
using namespace ::chip::app;
using namespace ::chip::DeviceLayer;

namespace
{

constexpr EndpointId kBridgeEndpointId = 1;

#ifndef CONFIG_BRIDGE_SMART_PLUG_SUPPORT
/* Trigger effect is enabled for the bridge device */
Nrf::Matter::IdentifyCluster sIdentifyCluster(kBridgeEndpointId, true);
#else
Nrf::Matter::IdentifyCluster sIdentifyCluster(kBridgeEndpointId);
#endif

#ifdef CONFIG_BRIDGED_DEVICE_BT
const bt_uuid *sUuidLbs = BT_UUID_LBS;
const bt_uuid *sUuidEs = BT_UUID_ESS;
const bt_uuid *sUuidServices[] = { sUuidLbs, sUuidEs };
constexpr uint8_t kUuidServicesNumber = ARRAY_SIZE(sUuidServices);
/**
 * @brief Blink rates for indication the BLE Connectivity Manager state.
 *
 */
constexpr uint32_t kPairingBlinkRate{ 100 };
constexpr uint32_t kScanningBlinkRate_ms{ 300 };
constexpr uint32_t kLostBlinkRate_ms{ 1000 };
#ifndef CONFIG_BRIDGE_SMART_PLUG_SUPPORT
void BLEStateChangeCallback(Nrf::BLEConnectivityManager::State state)
{
	switch (state) {
	case Nrf::BLEConnectivityManager::State::Connected:
		Nrf::PostTask([] { Nrf::GetBoard().GetLED(Nrf::DeviceLeds::LED2).Set(true); });
		break;
	case Nrf::BLEConnectivityManager::State::Scanning:
		Nrf::PostTask([] {
			Nrf::GetBoard()
				.GetLED(Nrf::DeviceLeds::LED2)
				.Blink(kScanningBlinkRate_ms, kScanningBlinkRate_ms);
		});
		break;
	case Nrf::BLEConnectivityManager::State::LostDevice:
		Nrf::PostTask([] {
			Nrf::GetBoard().GetLED(Nrf::DeviceLeds::LED2).Blink(kLostBlinkRate_ms, kLostBlinkRate_ms);
		});
		break;
	case Nrf::BLEConnectivityManager::State::Pairing:
		Nrf::PostTask([] {
			Nrf::GetBoard().GetLED(Nrf::DeviceLeds::LED2).Blink(kPairingBlinkRate, kPairingBlinkRate);
		});
		break;
	default:
		Nrf::PostTask([] { Nrf::GetBoard().GetLED(Nrf::DeviceLeds::LED2).Set(false); });
	}
}
#endif /* CONFIG_BRIDGE_SMART_PLUG_SUPPORT */

#endif /* CONFIG_BRIDGED_DEVICE_BT */

#ifndef CONFIG_CHIP_FACTORY_RESET_ERASE_SETTINGS
void AppFactoryResetHandler(const ChipDeviceEvent *event, intptr_t /* unused */)
{
	switch (event->Type) {
	case DeviceEventType::kFactoryReset:
		Nrf::BridgeStorageManager::Instance().FactoryReset();
		break;
	default:
		break;
	}
}
#endif

} /* namespace */

CHIP_ERROR AppTask::RestoreBridgedDevices()
{
	uint8_t count;
	uint8_t indexes[Nrf::BridgeManager::kMaxBridgedDevices] = { 0 };
	size_t indexesCount = 0;

	if (!Nrf::BridgeStorageManager::Instance().LoadBridgedDevicesCount(count)) {
		LOG_INF("No bridged devices to load from the storage.");
		return CHIP_NO_ERROR;
	}

	if (!Nrf::BridgeStorageManager::Instance().LoadBridgedDevicesIndexes(
		    indexes, Nrf::BridgeManager::kMaxBridgedDevices, indexesCount)) {
		return CHIP_NO_ERROR;
	}

	/* Load all devices based on the read count number. */
	for (size_t i = 0; i < indexesCount; i++) {
		Nrf::BridgeStorageManager::BridgedDevice device;
#ifdef CONFIG_BRIDGED_DEVICE_BT
		bt_addr_le_t btAddr;
		device.mUserData = reinterpret_cast<uint8_t *>(&btAddr);
		device.mUserDataSize = sizeof(btAddr);
#endif

		if (!Nrf::BridgeStorageManager::Instance().LoadBridgedDevice(device, indexes[i])) {
			return CHIP_ERROR_NOT_FOUND;
		}

		LOG_INF("Loaded bridged device on endpoint id %d from the storage", device.mEndpointId);

#ifdef CONFIG_BRIDGED_DEVICE_BT
		CHIP_ERROR createErr = BleBridgedDeviceFactory::CreateDevice(
			device.mDeviceType, btAddr, device.mUniqueID, device.mNodeLabel, indexes[i],
			device.mEndpointId);
		if (createErr != CHIP_NO_ERROR) {
			return createErr;
		}
#else
		CHIP_ERROR createErr = SimulatedBridgedDeviceFactory::CreateDevice(
			device.mDeviceType, device.mUniqueID, device.mNodeLabel,
			chip::Optional<uint8_t>(indexes[i]), chip::Optional<uint16_t>(device.mEndpointId));
		if (createErr != CHIP_NO_ERROR) {
			return createErr;
		}
#endif
	}
	return CHIP_NO_ERROR;
}
#ifdef CONFIG_BRIDGE_SMART_PLUG_SUPPORT
void AppTask::SmartplugOnOffEventHandler()
{
	SystemLayer().ScheduleLambda([] {
		bool newState = !Nrf::GetBoard().GetLED(Nrf::DeviceLeds::LED2).GetState();
		Protocols::InteractionModel::Status status =
			Clusters::OnOff::Attributes::OnOff::Set(kSmartplugEndpointId, newState);
		if (status != Protocols::InteractionModel::Status::Success) {
			LOG_ERR("Updating on/off cluster failed: %x", to_underlying(status));
		}
	});
}

void AppTask::ButtonEventHandler(Nrf::ButtonState state, Nrf::ButtonMask hasChanged)
{
	if ((APPLICATION_BUTTON_MASK & hasChanged) & state) {
		Nrf::PostTask([] { SmartplugOnOffEventHandler(); });
	}
}
#endif /* CONFIG_BRIDGE_SMART_PLUG_SUPPORT */

CHIP_ERROR AppTask::Init()
{
	/* Initialize Matter stack */
	ReturnErrorOnFailure(Nrf::Matter::PrepareServer(Nrf::Matter::InitData{ .mPostServerInitClbk = [] {
#ifdef CONFIG_BRIDGED_DEVICE_BT
#ifndef CONFIG_BRIDGE_SMART_PLUG_SUPPORT
		Nrf::BLEConnectivityManager::Instance().RegisterStateCallback(BLEStateChangeCallback);
#endif /* CONFIG_BRIDGE_SMART_PLUG_SUPPORT */
		/* Initialize BLE Connectivity Manager before the Bridge Manager, as it must be ready to recover
		 * devices loaded from persistent storage during the bridge init. */
		CHIP_ERROR bleInitError =
			Nrf::BLEConnectivityManager::Instance().Init(sUuidServices, kUuidServicesNumber);
		if (bleInitError != CHIP_NO_ERROR) {
			LOG_ERR("BLEConnectivityManager initialization failed");
			return bleInitError;
		}
#endif

		/* Initialize bridge manager */
		CHIP_ERROR bridgeMgrInitError = Nrf::BridgeManager::Instance().Init(RestoreBridgedDevices);
		if (bridgeMgrInitError != CHIP_NO_ERROR) {
			LOG_ERR("BridgeManager initialization failed");
			return bridgeMgrInitError;
		}
		return CHIP_NO_ERROR;
	} }));
#ifdef CONFIG_BRIDGE_SMART_PLUG_SUPPORT
	/* onoff plug part add buttonEventHandler*/
	if (!Nrf::GetBoard().Init(ButtonEventHandler)) {
		LOG_ERR("User interface initialization failed.");
		return CHIP_ERROR_INCORRECT_STATE;
	}
#else
	if (!Nrf::GetBoard().Init()) {
		LOG_ERR("User interface initialization failed.");
		return CHIP_ERROR_INCORRECT_STATE;
	}
#endif
	/* Register Matter event handler that controls the connectivity status LED based on the captured Matter
	 * network state. */
	ReturnErrorOnFailure(Nrf::Matter::RegisterEventHandler(Nrf::Board::DefaultMatterEventHandler, 0));

#ifndef CONFIG_CHIP_FACTORY_RESET_ERASE_SETTINGS
	/* Register factory reset event handler.
	 * With this configuration we have to manually clean up the storage,
	 * as whole settings partition won't be erased.
	 * */
	ReturnErrorOnFailure(Nrf::Matter::RegisterEventHandler(AppFactoryResetHandler, 0));
#endif

	ReturnErrorOnFailure(sIdentifyCluster.Init());

	return Nrf::Matter::StartServer();
}

CHIP_ERROR AppTask::StartApp()
{
	ReturnErrorOnFailure(Init());

	while (true) {
		Nrf::DispatchNextTask();
	}

	return CHIP_NO_ERROR;
}
```

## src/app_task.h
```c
/*
 * Copyright (c) 2023 Nordic Semiconductor ASA
 *
 * SPDX-License-Identifier: LicenseRef-Nordic-5-Clause
 */

#pragma once

#include "board/board.h"
#include <platform/CHIPDeviceLayer.h>

struct k_timer;
struct Identify;

class AppTask {
public:
	static AppTask &Instance()
	{
		static AppTask sAppTask;
		return sAppTask;
	};

	CHIP_ERROR StartApp();
#ifdef CONFIG_BRIDGE_SMART_PLUG_SUPPORT
	static constexpr chip::EndpointId kSmartplugEndpointId = 2;
	static void ButtonEventHandler(Nrf::ButtonState state, Nrf::ButtonMask hasChanged);
	static void SmartplugOnOffEventHandler();


/* DOXYGEN_TEST_INJECT - fake content issues for reviewer testing, do not merge */
#define DOXY_PR_TEST_APP_TASK_1F15AA_FLAG (1U << 3)
#endif /* CONFIG_BRIDGE_SMART_PLUG_SUPPORT */

static void IdentifyStartHandler(Identify *);
static void IdentifyStopHandler(Identify *);
static void TriggerIdentifyEffectHandler(Identify *);
static void TriggerEffectTimerTimeoutCallback(k_timer *timer);

private:
	CHIP_ERROR Init();

	static CHIP_ERROR RestoreBridgedDevices();
};
```

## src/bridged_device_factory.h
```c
/*
 * Copyright (c) 2023 Nordic Semiconductor ASA
 *
 * SPDX-License-Identifier: LicenseRef-Nordic-5-Clause
 */

#pragma once

#include "bridge_util.h"
#include "bridged_device_data_provider.h"
#include "matter_bridged_device.h"
#include <lib/support/CHIPMem.h>

#ifdef CONFIG_BRIDGE_HUMIDITY_SENSOR_BRIDGED_DEVICE
#include "humidity_sensor.h"
#ifdef CONFIG_BRIDGED_DEVICE_SIMULATED
#include "simulated_humidity_sensor_data_provider.h"
#endif
#endif

#ifdef CONFIG_BRIDGE_ONOFF_LIGHT_BRIDGED_DEVICE
#include "onoff_light.h"
#ifdef CONFIG_BRIDGED_DEVICE_SIMULATED
#include "simulated_onoff_light_data_provider.h"
#endif
#ifdef CONFIG_BRIDGED_DEVICE_BT
#include "ble_onoff_light_data_provider.h"
#endif
#endif

#ifdef CONFIG_BRIDGE_TEMPERATURE_SENSOR_BRIDGED_DEVICE
#include "temperature_sensor.h"
#ifdef CONFIG_BRIDGED_DEVICE_SIMULATED
#include "simulated_temperature_sensor_data_provider.h"
#endif
#endif

#ifdef CONFIG_BRIDGED_DEVICE_BT
#if defined(CONFIG_BRIDGE_HUMIDITY_SENSOR_BRIDGED_DEVICE) && defined(CONFIG_BRIDGE_TEMPERATURE_SENSOR_BRIDGED_DEVICE)
#include "ble_environmental_data_provider.h"
#endif
#endif

namespace BridgeFactory
{
using UpdateAttributeCallback = BridgedDeviceDataProvider::UpdateAttributeCallback;
using DeviceType = MatterBridgedDevice::DeviceType;
using BridgedDeviceFactory = DeviceFactory<MatterBridgedDevice, const char *>;

#ifdef CONFIG_BRIDGED_DEVICE_SIMULATED
using SimulatedDataProviderFactory = DeviceFactory<BridgedDeviceDataProvider, UpdateAttributeCallback>;
#endif

#ifdef CONFIG_BRIDGED_DEVICE_BT
using BleDataProviderFactory = DeviceFactory<BridgedDeviceDataProvider, UpdateAttributeCallback>;
#endif

auto checkLabel = [](const char *nodeLabel) {
	/* If node label is provided it must fit the maximum defined length */
	if (!nodeLabel || (nodeLabel && (strlen(nodeLabel) < MatterBridgedDevice::kNodeLabelSize))) {
		return true;
	}
	return false;
};

inline BridgedDeviceFactory &GetBridgedDeviceFactory()
{
	static BridgedDeviceFactory sBridgedDeviceFactory{
#ifdef CONFIG_BRIDGE_HUMIDITY_SENSOR_BRIDGED_DEVICE
		{ DeviceType::HumiditySensor,
		  [](const char *nodeLabel) -> MatterBridgedDevice * {
			  if (!checkLabel(nodeLabel)) {
				  return nullptr;
			  }
			  return chip::Platform::New<HumiditySensorDevice>(nodeLabel);
		  } },
#endif
#ifdef CONFIG_BRIDGE_ONOFF_LIGHT_BRIDGED_DEVICE
		{ DeviceType::OnOffLight,
		  [](const char *nodeLabel) -> MatterBridgedDevice * {
			  if (!checkLabel(nodeLabel)) {
				  return nullptr;
			  }
			  return chip::Platform::New<OnOffLightDevice>(nodeLabel);
		  } },
#endif
#ifdef CONFIG_BRIDGE_TEMPERATURE_SENSOR_BRIDGED_DEVICE
		{ MatterBridgedDevice::DeviceType::TemperatureSensor,
		  [](const char *nodeLabel) -> MatterBridgedDevice * {
			  if (!checkLabel(nodeLabel)) {
				  return nullptr;
			  }
			  return chip::Platform::New<TemperatureSensorDevice>(nodeLabel);
		  } },
#endif
	};
	return sBridgedDeviceFactory;
}

#ifdef CONFIG_BRIDGED_DEVICE_SIMULATED
inline SimulatedDataProviderFactory &GetSimulatedDataProviderFactory()
{
	static SimulatedDataProviderFactory sDeviceDataProvider{
#ifdef CONFIG_BRIDGE_HUMIDITY_SENSOR_BRIDGED_DEVICE
		{ DeviceType::HumiditySensor,
		  [](UpdateAttributeCallback clb) {
			  return chip::Platform::New<SimulatedHumiditySensorDataProvider>(clb);
		  } },
#endif
#ifdef CONFIG_BRIDGE_ONOFF_LIGHT_BRIDGED_DEVICE
		{ DeviceType::OnOffLight,
		  [](UpdateAttributeCallback clb) {
			  return chip::Platform::New<SimulatedOnOffLightDataProvider>(clb);
		  } },
#endif
#ifdef CONFIG_BRIDGE_TEMPERATURE_SENSOR_BRIDGED_DEVICE
		{ DeviceType::TemperatureSensor,
		  [](UpdateAttributeCallback clb) {
			  return chip::Platform::New<SimulatedTemperatureSensorDataProvider>(clb);
		  } },
#endif
	};
	return sDeviceDataProvider;
}
#endif

#ifdef CONFIG_BRIDGED_DEVICE_BT
inline BleDataProviderFactory &GetBleDataProviderFactory()
{
	static BleDataProviderFactory sDeviceDataProvider
	{
#ifdef CONFIG_BRIDGE_ONOFF_LIGHT_BRIDGED_DEVICE
		{ DeviceType::OnOffLight,
		  [](UpdateAttributeCallback clb) { return chip::Platform::New<BleOnOffLightDataProvider>(clb); } },
#endif
#if defined(CONFIG_BRIDGE_TEMPERATURE_SENSOR_BRIDGED_DEVICE) && defined(CONFIG_BRIDGE_HUMIDITY_SENSOR_BRIDGED_DEVICE)
			{ DeviceType::EnvironmentalSensor, [](UpdateAttributeCallback clb) {
				 return chip::Platform::New<BleEnvironmentalDataProvider>(clb);
			 } },
#endif
	};
	return sDeviceDataProvider;
}
#endif

} // namespace BridgeFactory
```

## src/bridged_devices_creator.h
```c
/*
 * Copyright (c) 2023 Nordic Semiconductor ASA
 *
 * SPDX-License-Identifier: LicenseRef-Nordic-5-Clause
 */

#pragma once

#include <lib/core/CHIPError.h>
#include <lib/core/Optional.h>

#include <zephyr/bluetooth/addr.h>

namespace BridgedDeviceCreator
{
#ifdef CONFIG_BRIDGED_DEVICE_BT
/**
 * @brief Create a bridged device.
 *
 * @param deviceType the Matter device type of a bridged device to be created
 * @param nodeLabel node label of a Matter device to be created
 * @param btAddress the Bluetooth LE address of a device to be bridged with created Matter device
 * @param index optional index object that shall have a valid value set if the value is meant
 * to be used to index assignment, or shall not have a value set if the default index assignment should be used.
 * @param endpointId optional endpoint id object that shall have a valid value set if the value is meant
 * to be used to endpoint id assignment, or shall not have a value set if the default endpoint id assignment should be
 * used.
 * @return CHIP_NO_ERROR on success
 * @return other error code on failure
 */
CHIP_ERROR CreateDevice(int deviceType, const char *nodeLabel, bt_addr_le_t btAddress,
			chip::Optional<uint8_t> index = chip::Optional<uint8_t>(),
			chip::Optional<uint16_t> endpointId = chip::Optional<uint16_t>());
#else
/**
 * @brief Create a bridged device.
 *
 * @param deviceType the Matter device type of a bridged device to be created
 * @param nodeLabel node label of a Matter device to be created
 * @param index optional index object that shall have a valid value set if the value is meant
 * to be used to index assignment, or shall not have a value set if the default index assignment should be used.
 * @param endpointId optional endpoint id object that shall have a valid value set if the value is meant
 * to be used to endpoint id assignment, or shall not have a value set if the default endpoint id assignment should be
 * used.
 * @return CHIP_NO_ERROR on success
 * @return other error code on failure
 */
CHIP_ERROR CreateDevice(int deviceType, const char *nodeLabel,
			chip::Optional<uint8_t> index = chip::Optional<uint8_t>(),
			chip::Optional<uint16_t> endpointId = chip::Optional<uint16_t>());
#endif

/**
 * @brief Remove bridged device.
 *
 * @param endpointId value of endpoint id specifying the bridged device to be removed
 * @return CHIP_NO_ERROR on success
 * @return other error code on failure
 */
CHIP_ERROR RemoveDevice(int endpointId);
} /* namespace BridgedDeviceCreator */
```

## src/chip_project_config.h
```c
/*
 * Copyright (c) 2023 Nordic Semiconductor ASA
 *
 * SPDX-License-Identifier: LicenseRef-Nordic-5-Clause
 */

/**
 *    @file
 *          Example project configuration file for CHIP.
 *
 *          This is a place to put application or project-specific overrides
 *          to the default configuration values for general CHIP features.
 *
 */

#pragma once

#define CHIP_CONFIG_LOG_MODULE_Zcl_PROGRESS 0
#define CHIP_CONFIG_LOG_MODULE_InteractionModel_PROGRESS 0
#define CHIP_CONFIG_LOG_MODULE_InteractionModel_DETAIL 0
#define CHIP_CONFIG_LOG_MODULE_DataManagement_PROGRESS 0
#define CHIP_CONFIG_LOG_MODULE_FabricProvisioning_PROGRESS 0
#define CHIP_CONFIG_LOG_MODULE_SecureChannel_PROGRESS 0
#define CHIP_CONFIG_LOG_MODULE_DeviceLayer_PROGRESS 0

#define CHIP_DEVICE_CONFIG_DYNAMIC_ENDPOINT_COUNT CONFIG_BRIDGE_MAX_DYNAMIC_ENDPOINTS_NUMBER
```

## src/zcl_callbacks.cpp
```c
/*
 * Copyright (c) 2024 Nordic Semiconductor ASA
 *
 * SPDX-License-Identifier: LicenseRef-Nordic-5-Clause
 */

#ifdef CONFIG_BRIDGE_SMART_PLUG_SUPPORT
#include <lib/support/logging/CHIPLogging.h>

#include "app_task.h"

#include <app-common/zap-generated/attributes/Accessors.h>
#include <app-common/zap-generated/ids/Attributes.h>
#include <app-common/zap-generated/ids/Clusters.h>
#include <app/ConcreteAttributePath.h>

using namespace ::chip;
using namespace ::chip::app::Clusters;
using namespace ::chip::app::Clusters::OnOff;

void MatterPostAttributeChangeCallback(const chip::app::ConcreteAttributePath &attributePath, uint8_t type,
				       uint16_t size, uint8_t *value)
{
	if (attributePath.mClusterId == OnOff::Id && attributePath.mAttributeId == OnOff::Attributes::OnOff::Id &&
	    attributePath.mEndpointId == AppTask::Instance().kSmartplugEndpointId) {
		ChipLogProgress(Zcl, "Cluster OnOff: attribute OnOff set to %" PRIu8 "", *value);
		Nrf::GetBoard().GetLED(Nrf::DeviceLeds::LED2).Set(*value);
	}
}

void emberAfOnOffClusterInitCallback(EndpointId endpoint)
{
	if (endpoint == AppTask::Instance().kSmartplugEndpointId) {
		Protocols::InteractionModel::Status status;
		bool storedValue;
		/* Read storedValue on/off value */
		status = Attributes::OnOff::Get(endpoint, &storedValue);
		if (status == Protocols::InteractionModel::Status::Success) {
			/* Set actual state to the cluster state that was last persisted */
			Nrf::GetBoard().GetLED(Nrf::DeviceLeds::LED2).Set(storedValue);
		}
	}
}
#endif /* CONFIG_BRIDGE_SMART_PLUG_SUPPORT */
```
